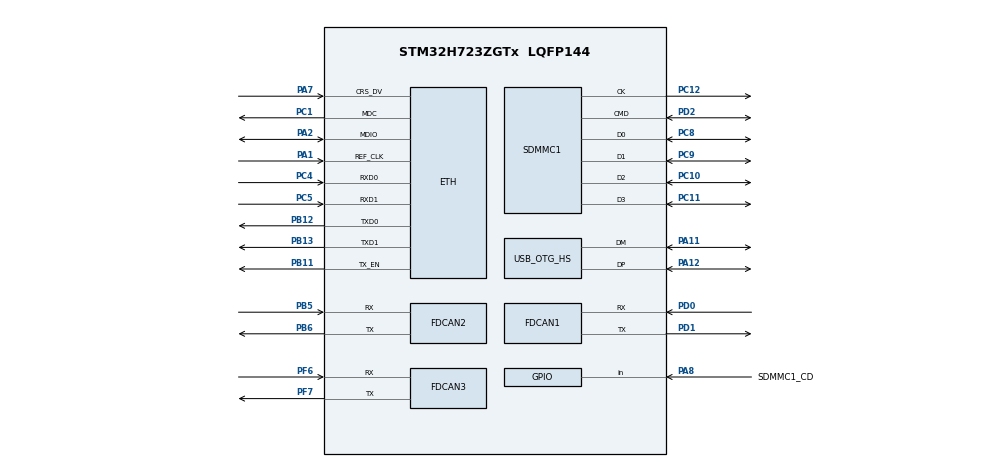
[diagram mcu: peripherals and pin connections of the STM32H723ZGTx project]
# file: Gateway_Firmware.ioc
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CORTEX_M7.CPU_DCache=Enabled
CORTEX_M7.CPU_ICache=Enabled
ETH.MediaInterface=HAL_ETH_RMII_MODE
FATFS.BSP.number=1
FATFS0.BSP.STBoard=false
FATFS0.BSP.api=Unknown
FATFS0.BSP.instance=PA8
FATFS0.BSP.ip=GPIO
FATFS0.BSP.mode=Input
FATFS0.BSP.name=Detect_SDIO
FATFS0.BSP.solution=PA8
FDCAN1.CalculateBaudRateNominal=1000000
FDCAN1.CalculateTimeBitNominal=1000
FDCAN1.CalculateTimeQuantumNominal=62.5
FDCAN1.ClockCalibrationCCU=DISABLE
FDCAN1.DataPrescaler=8
FDCAN1.DataTimeSeg1=13
FDCAN1.DataTimeSeg2=2
FDCAN1.NominalPrescaler=8
FDCAN1.NominalTimeSeg1=13
FDCAN2.CalculateBaudRateNominal=1600000
FDCAN2.CalculateTimeBitNominal=625
FDCAN2.CalculateTimeQuantumNominal=125.0
FDCAN3.CalculateBaudRateNominal=1600000
FDCAN3.CalculateTimeBitNominal=625
FDCAN3.CalculateTimeQuantumNominal=125.0
FREERTOS.Tasks01=defaultTask,19,8096,StartDefaultTask,Default,NULL,Dynamic,NULL,NULL;CANopenTask,40,1024,taskCANopen,Default,NULL,Dynamic,NULL,NULL
FREERTOS.configENABLE_FPU=1
FREERTOS.configMAX_TASK_NAME_LEN=30
FREERTOS.configTOTAL_HEAP_SIZE=131072
FREERTOS.configUSE_NEWLIB_REENTRANT=1
LWIP.BSP.number=1
LWIP.GATEWAY_ADDRESS=192.168.001.001
LWIP.IP_ADDRESS=192.168.001.255
LWIP.LWIP_DHCP=0
LWIP.LWIP_IGMP=1
LWIP.LWIP_MULTICAST_TX_OPTIONS=1
LWIP.MEMP_NUM_UDP_PCB=15
LWIP.MEM_SIZE=32*1024
LWIP.NETMASK_ADDRESS=255.255.255.000
LWIP.PBUF_POOL_SIZE=20
LWIP.TCPIP_THREAD_PRIO=20
LWIP.TCPIP_THREAD_STACKSIZE=1024*10
LWIP.Version=v2.1.2_Cube
LWIP0.BSP.STBoard=false
LWIP0.BSP.api=BSP_COMPONENT_DRIVER
LWIP0.BSP.component=LAN8742
LWIP0.BSP.instance=LAN8742
LWIP0.BSP.name=Driver_PHY
LWIP0.BSP.semaphore=S_LAN8742
LWIP0.BSP.solution=LAN8742
Mcu.Family=STM32H7
Mcu.Name=STM32H723ZGTx
Mcu.Package=LQFP144
NVIC.FDCAN1_IT0_IRQn=true\:5\:0\:false\:false\:true\:true\:true\:true\:true
NVIC.FDCAN1_IT1_IRQn=true\:5\:0\:false\:false\:true\:true\:true\:true\:true
NVIC.OTG_HS_IRQn=true\:5\:0\:false\:false\:true\:true\:false\:true\:true
NVIC.PriorityGroup=NVIC_PRIORITYGROUP_4
NVIC.TIM6_DAC_IRQn=true\:15\:0\:false\:false\:true\:false\:false\:true\:true
NVIC.TIM8_TRG_COM_TIM14_IRQn=true\:5\:0\:false\:false\:true\:true\:true\:true\:true
NVIC.TimeBase=TIM6_DAC_IRQn
NVIC.TimeBaseIP=TIM6
PA1.Mode=RMII
PA1.Signal=ETH_REF_CLK
PA11.Mode=Device_Only_FS
PA11.Signal=USB_OTG_HS_DM
PA12.Mode=Device_Only_FS
PA12.Signal=USB_OTG_HS_DP
PA13(JTMS/SWDIO).Mode=Trace_Asynchronous_SW
PA13(JTMS/SWDIO).Signal=DEBUG_JTMS-SWDIO
PA14(JTCK/SWCLK).Mode=Trace_Asynchronous_SW
PA14(JTCK/SWCLK).Signal=DEBUG_JTCK-SWCLK
PA2.Mode=RMII
PA2.Signal=ETH_MDIO
PA7.Mode=RMII
PA7.Signal=ETH_CRS_DV
PA8.GPIO_Label=SDMMC1_CD
PA8.Signal=GPIO_Input
PB11.Mode=RMII
PB11.Signal=ETH_TX_EN
PB12.Mode=RMII
PB12.Signal=ETH_TXD0
PB13.Mode=RMII
PB13.Signal=ETH_TXD1
PB3(JTDO/TRACESWO).Mode=Trace_Asynchronous_SW
PB3(JTDO/TRACESWO).Signal=DEBUG_JTDO-SWO
PB5.Mode=FDCAN_Activate
PB5.Signal=FDCAN2_RX
PB6.Mode=FDCAN_Activate
PB6.Signal=FDCAN2_TX
PC1.Mode=RMII
PC1.Signal=ETH_MDC
PC10.Mode=SD_4_bits_Wide_bus
PC10.Signal=SDMMC1_D2
PC11.Mode=SD_4_bits_Wide_bus
PC11.Signal=SDMMC1_D3
PC12.Mode=SD_4_bits_Wide_bus
PC12.Signal=SDMMC1_CK
PC14-OSC32_IN.Mode=LSE-External-Clock-Source
PC14-OSC32_IN.Signal=RCC_OSC32_IN
PC4.Mode=RMII
PC4.Signal=ETH_RXD0
PC5.Mode=RMII
PC5.Signal=ETH_RXD1
PC8.Mode=SD_4_bits_Wide_bus
PC8.Signal=SDMMC1_D0
PC9.Mode=SD_4_bits_Wide_bus
PC9.Signal=SDMMC1_D1
PD0.Mode=FDCAN_Activate
PD0.Signal=FDCAN1_RX
PD1.Mode=FDCAN_Activate
PD1.Signal=FDCAN1_TX
PD2.Mode=SD_4_bits_Wide_bus
PD2.Signal=SDMMC1_CMD
PF6.Mode=FDCAN_Activate
PF6.Signal=FDCAN3_RX
PF7.Mode=FDCAN_Activate
PF7.Signal=FDCAN3_TX
PH0-OSC_IN.Mode=HSE-External-Clock-Source
PH0-OSC_IN.Signal=RCC_OSC_IN
ProjectManager.HeapSize=0x200
ProjectManager.StackSize=0x400
ProjectManager.TargetToolchain=STM32CubeIDE
RCC.ADCFreq_Value=320000000
RCC.APB1Freq_Value=137500000
RCC.APB2Freq_Value=137500000
RCC.APB3Freq_Value=137500000
RCC.APB4Freq_Value=137500000
RCC.CortexFreq_Value=550000000
RCC.D1PPRE=RCC_APB3_DIV2
RCC.D2PPRE1=RCC_APB1_DIV2
RCC.D2PPRE2=RCC_APB2_DIV2
RCC.D3PPRE=RCC_APB4_DIV2
RCC.DIVM1=2
RCC.DIVM2=5
RCC.DIVN1=44
RCC.DIVN2=128
RCC.DIVP1=1
RCC.DIVQ1=5
RCC.DIVQ2=5
RCC.FDCANCLockSelection=RCC_FDCANCLKSOURCE_PLL2
RCC.HCLKFreq_Value=275000000
RCC.HPRE=RCC_HCLK_DIV2
RCC.PLL2FRACN=0
RCC.PLL3FRACN=0
RCC.PLLFRACN=0
RCC.SYSCLKFreq_VALUE=550000000
RCC.SYSCLKSource=RCC_SYSCLKSOURCE_PLLCLK
RCC.USBFreq_Value=110000000
TIM14.Period=100
TIM14.Prescaler=1374
USB_DEVICE.CLASS_NAME_HS=CDC
USB_DEVICE.VirtualMode=Cdc
USB_DEVICE.VirtualModeHS=Cdc_HS
USB_OTG_HS.VirtualMode-Device_Only_FS=Device_Only_FS
VP_DTS_VS-DTS.Mode=DTS
VP_FATFS_VS_SDIO.Mode=SDIO
VP_FREERTOS_VS_CMSIS_V2.Mode=CMSIS_V2
VP_LWIP_VS_Enabled.Mode=Enabled
VP_SYS_VS_tim6.Mode=TIM6
VP_TIM14_VS_ClockSourceINT.Mode=Enable_Timer
VP_USB_DEVICE_VS_USB_DEVICE_CDC_HS.Mode=CDC_HS
board=custom

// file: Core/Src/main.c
/* USER CODE BEGIN Header */
/**
  ******************************************************************************
  * @file           : main.c
  * @brief          : Main program body
  ******************************************************************************
  * @attention
  *
  * Copyright (c) 2023 STMicroelectronics.
  * All rights reserved.
  *
  * This software is licensed under terms that can be found in the LICENSE file
  * in the root directory of this software component.
  * If no LICENSE file comes with this software, it is provided AS-IS.
  *
  ******************************************************************************
  */
/* USER CODE END Header */
#include "main.h"
#include "cmsis_os.h"
#include "dts.h"
#include "fatfs.h"
#include "fdcan.h"
#include "lwip.h"
#include "sdmmc.h"
#include "tim.h"
#include "usb_device.h"
#include "gpio.h"

/* USER CODE BEGIN Includes */
#include "config.h"
#include "CO_app_STM32.h"
/* USER CODE END Includes */

void SystemClock_Config(void);
void PeriphCommonClock_Config(void);
void MX_FREERTOS_Init(void);

int main(void)
{

  /* Enable I-Cache---------------------------------------------------------*/
  SCB_EnableICache();

  /* Enable D-Cache---------------------------------------------------------*/
  SCB_EnableDCache();

  /* MCU Configuration--------------------------------------------------------*/

  /* Reset of all peripherals, Initializes the Flash interface and the Systick. */
  HAL_Init();

  /* Configure the system clock */
  SystemClock_Config();

/* Configure the peripherals common clocks */
  PeriphCommonClock_Config();

  /* Initialize all configured peripherals */
  MX_GPIO_Init();
  MX_DTS_Init();
  MX_FDCAN1_Init();
  MX_FDCAN2_Init();
  MX_SDMMC1_SD_Init();
  MX_FATFS_Init();
  MX_TIM14_Init();
  MX_FDCAN3_Init();
  /* USER CODE BEGIN 2 */

  CANopenNodeSTM32 canOpenNodeSTM32;
  canOpenNodeSTM32.CANHandle = &hfdcan1;
  canOpenNodeSTM32.HWInitFunction = MX_FDCAN1_Init;
  canOpenNodeSTM32.timerHandle = &htim14;
  canOpenNodeSTM32.desiredNodeID = CAN_OPEN_ID;
  canOpenNodeSTM32.baudrate = CAN_OPEN_BAUDRATE;
  canopen_app_init(&canOpenNodeSTM32);

  /* USER CODE END 2 */

  /* Init scheduler */
  osKernelInitialize();  /* Call init function for freertos objects (in freertos.c) */
  MX_FREERTOS_Init();

  /* Start scheduler */
  osKernelStart();
  /* We should never get here as control is now taken by the scheduler */
  /* Infinite loop */
  while (1)
  {

  }
}

void SystemClock_Config(void)
{
  RCC_OscInitTypeDef RCC_OscInitStruct = {0};
  RCC_ClkInitTypeDef RCC_ClkInitStruct = {0};

  /** Supply configuration update enable
  */
  HAL_PWREx_ConfigSupply(PWR_LDO_SUPPLY);

  /** Configure the main internal regulator output voltage
  */
  __HAL_PWR_VOLTAGESCALING_CONFIG(PWR_REGULATOR_VOLTAGE_SCALE0);

  while(!__HAL_PWR_GET_FLAG(PWR_FLAG_VOSRDY)) {}

  /** Initializes the RCC Oscillators according to the specified parameters
  * in the RCC_OscInitTypeDef structure.
  */
  RCC_OscInitStruct.OscillatorType = RCC_OSCILLATORTYPE_HSE;
  RCC_OscInitStruct.HSEState = RCC_HSE_BYPASS;
  RCC_OscInitStruct.PLL.PLLState = RCC_PLL_ON;
  RCC_OscInitStruct.PLL.PLLSource = RCC_PLLSOURCE_HSE;
  RCC_OscInitStruct.PLL.PLLM = 2;
  RCC_OscInitStruct.PLL.PLLN = 44;
  RCC_OscInitStruct.PLL.PLLP = 1;
  RCC_OscInitStruct.PLL.PLLQ = 5;
  RCC_OscInitStruct.PLL.PLLR = 2;
  RCC_OscInitStruct.PLL.PLLRGE = RCC_PLL1VCIRANGE_3;
  RCC_OscInitStruct.PLL.PLLVCOSEL = RCC_PLL1VCOWIDE;
  RCC_OscInitStruct.PLL.PLLFRACN = 0;
  if (HAL_RCC_OscConfig(&RCC_OscInitStruct) != HAL_OK)
  {
    Error_Handler();
  }

  /** Initializes the CPU, AHB and APB buses clocks
  */
  RCC_ClkInitStruct.ClockType = RCC_CLOCKTYPE_HCLK|RCC_CLOCKTYPE_SYSCLK
                              |RCC_CLOCKTYPE_PCLK1|RCC_CLOCKTYPE_PCLK2
                              |RCC_CLOCKTYPE_D3PCLK1|RCC_CLOCKTYPE_D1PCLK1;
  RCC_ClkInitStruct.SYSCLKSource = RCC_SYSCLKSOURCE_PLLCLK;
  RCC_ClkInitStruct.SYSCLKDivider = RCC_SYSCLK_DIV1;
  RCC_ClkInitStruct.AHBCLKDivider = RCC_HCLK_DIV2;
  RCC_ClkInitStruct.APB3CLKDivider = RCC_APB3_DIV2;
  RCC_ClkInitStruct.APB1CLKDivider = RCC_APB1_DIV2;
  RCC_ClkInitStruct.APB2CLKDivider = RCC_APB2_DIV2;
  RCC_ClkInitStruct.APB4CLKDivider = RCC_APB4_DIV2;

  if (HAL_RCC_ClockConfig(&RCC_ClkInitStruct, FLASH_LATENCY_3) != HAL_OK)
  {
    Error_Handler();
  }
}

void PeriphCommonClock_Config(void)
{
  RCC_PeriphCLKInitTypeDef PeriphClkInitStruct = {0};

  /** Initializes the peripherals clock
  */
  PeriphClkInitStruct.PeriphClockSelection = RCC_PERIPHCLK_FDCAN;
  PeriphClkInitStruct.PLL2.PLL2M = 5;
  PeriphClkInitStruct.PLL2.PLL2N = 128;
  PeriphClkInitStruct.PLL2.PLL2P = 2;
  PeriphClkInitStruct.PLL2.PLL2Q = 5;
  PeriphClkInitStruct.PLL2.PLL2R = 2;
  PeriphClkInitStruct.PLL2.PLL2RGE = RCC_PLL2VCIRANGE_2;
  PeriphClkInitStruct.PLL2.PLL2VCOSEL = RCC_PLL2VCOWIDE;
  PeriphClkInitStruct.PLL2.PLL2FRACN = 0;
  PeriphClkInitStruct.FdcanClockSelection = RCC_FDCANCLKSOURCE_PLL2;
  if (HAL_RCCEx_PeriphCLKConfig(&PeriphClkInitStruct) != HAL_OK)
  {
    Error_Handler();
  }
}

void HAL_TIM_PeriodElapsedCallback(TIM_HandleTypeDef *htim)
{
  if (htim->Instance == TIM6) {
    HAL_IncTick();
  }
  /* USER CODE BEGIN Callback 1 */

  /* CANopen timer interrupt function executes every 1 ms */
  else if (htim == canopenNodeSTM32->timerHandle) {
      canopen_app_interrupt();
  }

  /* USER CODE END Callback 1 */
}

void Error_Handler(void)
{
  __disable_irq();
  while (1)
  {
  }
}

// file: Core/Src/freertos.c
/* USER CODE BEGIN Header */
/**
  ******************************************************************************
  * File Name          : freertos.c
  * Description        : Code for freertos applications
  ******************************************************************************
  * @attention
  *
  * Copyright (c) 2023 STMicroelectronics.
  * All rights reserved.
  *
  * This software is licensed under terms that can be found in the LICENSE file
  * in the root directory of this software component.
  * If no LICENSE file comes with this software, it is provided AS-IS.
  *
  ******************************************************************************
  */
/* USER CODE END Header */

#include "FreeRTOS.h"
#include "task.h"
#include "main.h"
#include "cmsis_os.h"

/* USER CODE BEGIN Includes */
#include "CO_app_STM32.h"
#include "fdcan.h"
#include "tim.h"
/* USER CODE END Includes */

/* Definitions for defaultTask */
osThreadId_t defaultTaskHandle;
const osThreadAttr_t defaultTask_attributes = {
  .name = "defaultTask",
  .stack_size = 8096 * 4,
  .priority = (osPriority_t) osPriorityBelowNormal3,
};
/* Definitions for CANopenTask */
osThreadId_t CANopenTaskHandle;
const osThreadAttr_t CANopenTask_attributes = {
  .name = "CANopenTask",
  .stack_size = 1024 * 4,
  .priority = (osPriority_t) osPriorityHigh,
};

void StartDefaultTask(void *argument);
void taskCANopen(void *argument);

extern void MX_LWIP_Init(void);
extern void MX_USB_DEVICE_Init(void);
void MX_FREERTOS_Init(void); /* (MISRA C 2004 rule 8.1) */

void MX_FREERTOS_Init(void) {

  /* Create the thread(s) */
  /* creation of defaultTask */
  defaultTaskHandle = osThreadNew(StartDefaultTask, NULL, &defaultTask_attributes);

  /* creation of CANopenTask */
  CANopenTaskHandle = osThreadNew(taskCANopen, NULL, &CANopenTask_attributes);

}

void StartDefaultTask(void *argument)
{
  /* init code for LWIP */
  MX_LWIP_Init();

  /* init code for USB_DEVICE */
  MX_USB_DEVICE_Init();
  for(;;)
  {
    osDelay(1);
  }
}

void taskCANopen(void *argument)
{
  for(;;)
  {
    osDelay(1);
  }
}
